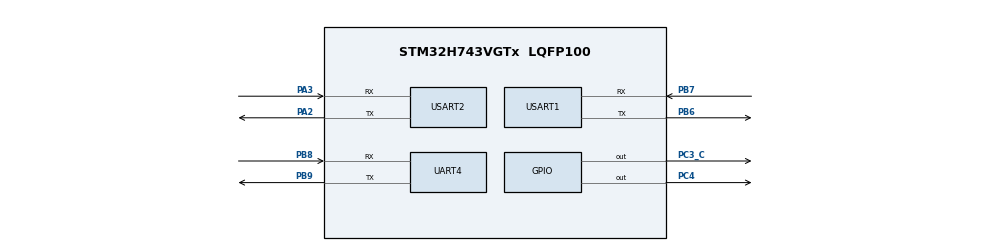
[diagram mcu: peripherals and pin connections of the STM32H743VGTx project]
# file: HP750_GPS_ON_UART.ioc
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Dma.Request0=USART2_RX
Dma.Request1=USART1_TX
Dma.Request2=USART1_RX
Dma.Request3=USART2_TX
Dma.USART1_RX.2.Direction=DMA_PERIPH_TO_MEMORY
Dma.USART1_RX.2.EventEnable=DISABLE
Dma.USART1_RX.2.FIFOMode=DMA_FIFOMODE_DISABLE
Dma.USART1_RX.2.Instance=DMA1_Stream2
Dma.USART1_RX.2.MemDataAlignment=DMA_MDATAALIGN_BYTE
Dma.USART1_RX.2.MemInc=DMA_MINC_ENABLE
Dma.USART1_RX.2.Mode=DMA_NORMAL
Dma.USART1_RX.2.PeriphDataAlignment=DMA_PDATAALIGN_BYTE
Dma.USART1_RX.2.PeriphInc=DMA_PINC_DISABLE
Dma.USART1_RX.2.Polarity=HAL_DMAMUX_REQ_GEN_RISING
Dma.USART1_RX.2.Priority=DMA_PRIORITY_LOW
Dma.USART1_RX.2.RequestNumber=1
Dma.USART1_RX.2.SignalID=NONE
Dma.USART1_RX.2.SyncEnable=DISABLE
Dma.USART1_RX.2.SyncPolarity=HAL_DMAMUX_SYNC_NO_EVENT
Dma.USART1_RX.2.SyncRequestNumber=1
Dma.USART1_RX.2.SyncSignalID=NONE
Dma.USART1_TX.1.Direction=DMA_MEMORY_TO_PERIPH
Dma.USART1_TX.1.EventEnable=DISABLE
Dma.USART1_TX.1.FIFOMode=DMA_FIFOMODE_DISABLE
Dma.USART1_TX.1.Instance=DMA1_Stream0
Dma.USART1_TX.1.MemDataAlignment=DMA_MDATAALIGN_BYTE
Dma.USART1_TX.1.MemInc=DMA_MINC_ENABLE
Dma.USART1_TX.1.Mode=DMA_NORMAL
Dma.USART1_TX.1.PeriphDataAlignment=DMA_PDATAALIGN_BYTE
Dma.USART1_TX.1.PeriphInc=DMA_PINC_DISABLE
Dma.USART1_TX.1.Polarity=HAL_DMAMUX_REQ_GEN_RISING
Dma.USART1_TX.1.Priority=DMA_PRIORITY_LOW
Dma.USART1_TX.1.RequestNumber=1
Dma.USART1_TX.1.SignalID=NONE
Dma.USART1_TX.1.SyncEnable=DISABLE
Dma.USART1_TX.1.SyncPolarity=HAL_DMAMUX_SYNC_NO_EVENT
Dma.USART1_TX.1.SyncRequestNumber=1
Dma.USART1_TX.1.SyncSignalID=NONE
Dma.USART2_RX.0.Direction=DMA_PERIPH_TO_MEMORY
Dma.USART2_RX.0.EventEnable=DISABLE
Dma.USART2_RX.0.FIFOMode=DMA_FIFOMODE_DISABLE
Dma.USART2_RX.0.Instance=DMA1_Stream1
Dma.USART2_RX.0.MemDataAlignment=DMA_MDATAALIGN_BYTE
Dma.USART2_RX.0.MemInc=DMA_MINC_ENABLE
Dma.USART2_RX.0.Mode=DMA_NORMAL
Dma.USART2_RX.0.PeriphDataAlignment=DMA_PDATAALIGN_BYTE
Dma.USART2_RX.0.PeriphInc=DMA_PINC_DISABLE
Dma.USART2_RX.0.Polarity=HAL_DMAMUX_REQ_GEN_RISING
Dma.USART2_RX.0.Priority=DMA_PRIORITY_LOW
Dma.USART2_RX.0.RequestNumber=1
Dma.USART2_RX.0.SignalID=NONE
Dma.USART2_RX.0.SyncEnable=DISABLE
Dma.USART2_RX.0.SyncPolarity=HAL_DMAMUX_SYNC_NO_EVENT
Dma.USART2_RX.0.SyncRequestNumber=1
Dma.USART2_RX.0.SyncSignalID=NONE
Dma.USART2_TX.3.Direction=DMA_MEMORY_TO_PERIPH
Dma.USART2_TX.3.EventEnable=DISABLE
Dma.USART2_TX.3.FIFOMode=DMA_FIFOMODE_DISABLE
Dma.USART2_TX.3.Instance=DMA1_Stream3
Dma.USART2_TX.3.MemDataAlignment=DMA_MDATAALIGN_BYTE
Dma.USART2_TX.3.MemInc=DMA_MINC_ENABLE
Dma.USART2_TX.3.Mode=DMA_NORMAL
Dma.USART2_TX.3.PeriphDataAlignment=DMA_PDATAALIGN_BYTE
Dma.USART2_TX.3.PeriphInc=DMA_PINC_DISABLE
Dma.USART2_TX.3.Polarity=HAL_DMAMUX_REQ_GEN_RISING
Dma.USART2_TX.3.Priority=DMA_PRIORITY_LOW
Dma.USART2_TX.3.RequestNumber=1
Dma.USART2_TX.3.SignalID=NONE
Dma.USART2_TX.3.SyncEnable=DISABLE
Dma.USART2_TX.3.SyncPolarity=HAL_DMAMUX_SYNC_NO_EVENT
Dma.USART2_TX.3.SyncRequestNumber=1
Dma.USART2_TX.3.SyncSignalID=NONE
Mcu.Family=STM32H7
Mcu.Name=STM32H743VGTx
Mcu.Package=LQFP100
NVIC.DMA1_Stream0_IRQn=true\:0\:0\:false\:false\:true\:false\:true\:true
NVIC.DMA1_Stream1_IRQn=true\:0\:0\:false\:false\:true\:false\:true\:true
NVIC.DMA1_Stream2_IRQn=true\:0\:0\:false\:false\:true\:false\:true\:true
NVIC.DMA1_Stream3_IRQn=true\:0\:0\:false\:false\:true\:false\:true\:true
NVIC.PriorityGroup=NVIC_PRIORITYGROUP_4
NVIC.UART4_IRQn=true\:0\:0\:false\:false\:true\:true\:true\:true
NVIC.USART1_IRQn=true\:0\:0\:false\:false\:true\:true\:true\:true
NVIC.USART2_IRQn=true\:0\:0\:false\:false\:true\:true\:true\:true
PA13\ (JTMS/SWDIO).Mode=Serial_Wire
PA13\ (JTMS/SWDIO).Signal=DEBUG_JTMS-SWDIO
PA14\ (JTCK/SWCLK).Mode=Serial_Wire
PA14\ (JTCK/SWCLK).Signal=DEBUG_JTCK-SWCLK
PA2.Mode=Asynchronous
PA2.Signal=USART2_TX
PA3.Mode=Asynchronous
PA3.Signal=USART2_RX
PB6.Mode=Asynchronous
PB6.Signal=USART1_TX
PB7.Mode=Asynchronous
PB7.Signal=USART1_RX
PB8.Mode=Asynchronous
PB8.Signal=UART4_RX
PB9.Mode=Asynchronous
PB9.Signal=UART4_TX
PC14-OSC32_IN\ (OSC32_IN).Mode=LSE-External-Oscillator
PC14-OSC32_IN\ (OSC32_IN).Signal=RCC_OSC32_IN
PC15-OSC32_OUT\ (OSC32_OUT).Mode=LSE-External-Oscillator
PC15-OSC32_OUT\ (OSC32_OUT).Signal=RCC_OSC32_OUT
PC3_C.Signal=GPIO_Output
PC4.Signal=GPIO_Output
PH0-OSC_IN\ (PH0).Mode=HSE-External-Oscillator
PH0-OSC_IN\ (PH0).Signal=RCC_OSC_IN
PH1-OSC_OUT\ (PH1).Mode=HSE-External-Oscillator
PH1-OSC_OUT\ (PH1).Signal=RCC_OSC_OUT
ProjectManager.HeapSize=0x200
ProjectManager.StackSize=0x400
ProjectManager.TargetToolchain=STM32CubeIDE
RCC.ADCFreq_Value=129000000
RCC.APB1Freq_Value=32000000
RCC.APB2Freq_Value=32000000
RCC.APB3Freq_Value=64000000
RCC.APB4Freq_Value=64000000
RCC.CortexFreq_Value=64000000
RCC.D2PPRE1=RCC_APB1_DIV2
RCC.D2PPRE2=RCC_APB2_DIV2
RCC.HCLKFreq_Value=64000000
RCC.HSE_VALUE=16000000
RCC.SYSCLKFreq_VALUE=64000000
RCC.USBFreq_Value=129000000
USART1.VirtualMode-Asynchronous=VM_ASYNC
USART2.VirtualMode-Asynchronous=VM_ASYNC
board=custom

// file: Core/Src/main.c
/* USER CODE BEGIN Header */
/**
  ******************************************************************************
  * @file           : main.c
  * @brief          : Main program body
  ******************************************************************************
  * @attention
  *
  * Copyright (c) 2023 STMicroelectronics.
  * All rights reserved.
  *
  * This software is licensed under terms that can be found in the LICENSE file
  * in the root directory of this software component.
  * If no LICENSE file comes with this software, it is provided AS-IS.
  *
  ******************************************************************************
  */
/* USER CODE END Header */
#include "main.h"

UART_HandleTypeDef huart4;
UART_HandleTypeDef huart1;
UART_HandleTypeDef huart2;
DMA_HandleTypeDef hdma_usart1_tx;
DMA_HandleTypeDef hdma_usart1_rx;
DMA_HandleTypeDef hdma_usart2_rx;
DMA_HandleTypeDef hdma_usart2_tx;

void SystemClock_Config(void);
static void MX_GPIO_Init(void);
static void MX_DMA_Init(void);
static void MX_USART1_UART_Init(void);
static void MX_UART4_Init(void);
static void MX_USART2_UART_Init(void);

/* USER CODE BEGIN 0 */
// Global variables
uint8_t uart2_rx_buffer[300];
uint8_t uart1_tx_buffer[300];

// UART1 receive complete callback
void HAL_UART_RxCpltCallback(UART_HandleTypeDef *huart) {
    if (huart == &huart2) {
        // UART4 data received, copy to UART1 TX buffer
        HAL_UART_Transmit_DMA(&huart1, uart2_rx_buffer, 200);
    }
}

// UART1 transmit complete callback
void HAL_UART_TxCpltCallback(UART_HandleTypeDef *huart) {
    if (huart == &huart1) {
        // UART1 data transmitted, can add additional processing here
    }
}
/* USER CODE END 0 */

int main(void)
{

  /* MCU Configuration--------------------------------------------------------*/

  /* Reset of all peripherals, Initializes the Flash interface and the Systick. */
  HAL_Init();

  /* Configure the system clock */
  SystemClock_Config();

  /* Initialize all configured peripherals */
  MX_GPIO_Init();
  MX_DMA_Init();
  MX_USART1_UART_Init();
  MX_UART4_Init();
  MX_USART2_UART_Init();
  /* USER CODE BEGIN 2 */
  HAL_GPIO_WritePin(GPIOC, GPIO_PIN_4, GPIO_PIN_SET);
  HAL_Delay(500);
  HAL_GPIO_WritePin(GPIOC, GPIO_PIN_3, GPIO_PIN_RESET);
  HAL_Delay(100);
  HAL_GPIO_WritePin(GPIOC, GPIO_PIN_3, GPIO_PIN_SET);

  /* USER CODE END 2 */

  /* Infinite loop */
  /* USER CODE BEGIN WHILE */

  while (1)
  {
	  // Start UART1 DMA receive
	     HAL_UART_Receive_DMA(&huart2, uart2_rx_buffer, 200);

    /* USER CODE END WHILE */

  }
}

void SystemClock_Config(void)
{
  RCC_OscInitTypeDef RCC_OscInitStruct = {0};
  RCC_ClkInitTypeDef RCC_ClkInitStruct = {0};

  /** Supply configuration update enable
  */
  HAL_PWREx_ConfigSupply(PWR_LDO_SUPPLY);

  /** Configure the main internal regulator output voltage
  */
  __HAL_PWR_VOLTAGESCALING_CONFIG(PWR_REGULATOR_VOLTAGE_SCALE3);

  while(!__HAL_PWR_GET_FLAG(PWR_FLAG_VOSRDY)) {}

  /** Initializes the RCC Oscillators according to the specified parameters
  * in the RCC_OscInitTypeDef structure.
  */
  RCC_OscInitStruct.OscillatorType = RCC_OSCILLATORTYPE_HSI;
  RCC_OscInitStruct.HSIState = RCC_HSI_DIV1;
  RCC_OscInitStruct.HSICalibrationValue = RCC_HSICALIBRATION_DEFAULT;
  RCC_OscInitStruct.PLL.PLLState = RCC_PLL_NONE;
  if (HAL_RCC_OscConfig(&RCC_OscInitStruct) != HAL_OK)
  {
    Error_Handler();
  }

  /** Initializes the CPU, AHB and APB buses clocks
  */
  RCC_ClkInitStruct.ClockType = RCC_CLOCKTYPE_HCLK|RCC_CLOCKTYPE_SYSCLK
                              |RCC_CLOCKTYPE_PCLK1|RCC_CLOCKTYPE_PCLK2
                              |RCC_CLOCKTYPE_D3PCLK1|RCC_CLOCKTYPE_D1PCLK1;
  RCC_ClkInitStruct.SYSCLKSource = RCC_SYSCLKSOURCE_HSI;
  RCC_ClkInitStruct.SYSCLKDivider = RCC_SYSCLK_DIV1;
  RCC_ClkInitStruct.AHBCLKDivider = RCC_HCLK_DIV1;
  RCC_ClkInitStruct.APB3CLKDivider = RCC_APB3_DIV1;
  RCC_ClkInitStruct.APB1CLKDivider = RCC_APB1_DIV2;
  RCC_ClkInitStruct.APB2CLKDivider = RCC_APB2_DIV2;
  RCC_ClkInitStruct.APB4CLKDivider = RCC_APB4_DIV1;

  if (HAL_RCC_ClockConfig(&RCC_ClkInitStruct, FLASH_LATENCY_1) != HAL_OK)
  {
    Error_Handler();
  }
}

static void MX_UART4_Init(void)
{

  huart4.Instance = UART4;
  huart4.Init.BaudRate = 115200;
  huart4.Init.WordLength = UART_WORDLENGTH_8B;
  huart4.Init.StopBits = UART_STOPBITS_1;
  huart4.Init.Parity = UART_PARITY_NONE;
  huart4.Init.Mode = UART_MODE_TX_RX;
  huart4.Init.HwFlowCtl = UART_HWCONTROL_NONE;
  huart4.Init.OverSampling = UART_OVERSAMPLING_16;
  huart4.Init.OneBitSampling = UART_ONE_BIT_SAMPLE_DISABLE;
  huart4.Init.ClockPrescaler = UART_PRESCALER_DIV1;
  huart4.AdvancedInit.AdvFeatureInit = UART_ADVFEATURE_NO_INIT;
  if (HAL_UART_Init(&huart4) != HAL_OK)
  {
    Error_Handler();
  }
  if (HAL_UARTEx_SetTxFifoThreshold(&huart4, UART_TXFIFO_THRESHOLD_1_8) != HAL_OK)
  {
    Error_Handler();
  }
  if (HAL_UARTEx_SetRxFifoThreshold(&huart4, UART_RXFIFO_THRESHOLD_1_8) != HAL_OK)
  {
    Error_Handler();
  }
  if (HAL_UARTEx_DisableFifoMode(&huart4) != HAL_OK)
  {
    Error_Handler();
  }

}

static void MX_USART1_UART_Init(void)
{

  huart1.Instance = USART1;
  huart1.Init.BaudRate = 115200;
  huart1.Init.WordLength = UART_WORDLENGTH_8B;
  huart1.Init.StopBits = UART_STOPBITS_1;
  huart1.Init.Parity = UART_PARITY_NONE;
  huart1.Init.Mode = UART_MODE_TX_RX;
  huart1.Init.HwFlowCtl = UART_HWCONTROL_NONE;
  huart1.Init.OverSampling = UART_OVERSAMPLING_16;
  huart1.Init.OneBitSampling = UART_ONE_BIT_SAMPLE_DISABLE;
  huart1.Init.ClockPrescaler = UART_PRESCALER_DIV1;
  huart1.AdvancedInit.AdvFeatureInit = UART_ADVFEATURE_NO_INIT;
  if (HAL_UART_Init(&huart1) != HAL_OK)
  {
    Error_Handler();
  }
  if (HAL_UARTEx_SetTxFifoThreshold(&huart1, UART_TXFIFO_THRESHOLD_1_8) != HAL_OK)
  {
    Error_Handler();
  }
  if (HAL_UARTEx_SetRxFifoThreshold(&huart1, UART_RXFIFO_THRESHOLD_1_8) != HAL_OK)
  {
    Error_Handler();
  }
  if (HAL_UARTEx_DisableFifoMode(&huart1) != HAL_OK)
  {
    Error_Handler();
  }

}

static void MX_USART2_UART_Init(void)
{

  huart2.Instance = USART2;
  huart2.Init.BaudRate = 115200;
  huart2.Init.WordLength = UART_WORDLENGTH_8B;
  huart2.Init.StopBits = UART_STOPBITS_1;
  huart2.Init.Parity = UART_PARITY_NONE;
  huart2.Init.Mode = UART_MODE_TX_RX;
  huart2.Init.HwFlowCtl = UART_HWCONTROL_NONE;
  huart2.Init.OverSampling = UART_OVERSAMPLING_16;
  huart2.Init.OneBitSampling = UART_ONE_BIT_SAMPLE_DISABLE;
  huart2.Init.ClockPrescaler = UART_PRESCALER_DIV1;
  huart2.AdvancedInit.AdvFeatureInit = UART_ADVFEATURE_NO_INIT;
  if (HAL_UART_Init(&huart2) != HAL_OK)
  {
    Error_Handler();
  }
  if (HAL_UARTEx_SetTxFifoThreshold(&huart2, UART_TXFIFO_THRESHOLD_1_8) != HAL_OK)
  {
    Error_Handler();
  }
  if (HAL_UARTEx_SetRxFifoThreshold(&huart2, UART_RXFIFO_THRESHOLD_1_8) != HAL_OK)
  {
    Error_Handler();
  }
  if (HAL_UARTEx_DisableFifoMode(&huart2) != HAL_OK)
  {
    Error_Handler();
  }

}

static void MX_DMA_Init(void)
{

  /* DMA controller clock enable */
  __HAL_RCC_DMA1_CLK_ENABLE();

  /* DMA interrupt init */
  /* DMA1_Stream0_IRQn interrupt configuration */
  HAL_NVIC_SetPriority(DMA1_Stream0_IRQn, 0, 0);
  HAL_NVIC_EnableIRQ(DMA1_Stream0_IRQn);
  /* DMA1_Stream1_IRQn interrupt configuration */
  HAL_NVIC_SetPriority(DMA1_Stream1_IRQn, 0, 0);
  HAL_NVIC_EnableIRQ(DMA1_Stream1_IRQn);
  /* DMA1_Stream2_IRQn interrupt configuration */
  HAL_NVIC_SetPriority(DMA1_Stream2_IRQn, 0, 0);
  HAL_NVIC_EnableIRQ(DMA1_Stream2_IRQn);
  /* DMA1_Stream3_IRQn interrupt configuration */
  HAL_NVIC_SetPriority(DMA1_Stream3_IRQn, 0, 0);
  HAL_NVIC_EnableIRQ(DMA1_Stream3_IRQn);

}

static void MX_GPIO_Init(void)
{
  GPIO_InitTypeDef GPIO_InitStruct = {0};

  /* GPIO Ports Clock Enable */
  __HAL_RCC_GPIOC_CLK_ENABLE();
  __HAL_RCC_GPIOH_CLK_ENABLE();
  __HAL_RCC_GPIOA_CLK_ENABLE();
  __HAL_RCC_GPIOB_CLK_ENABLE();

  /*Configure GPIO pin Output Level */
  HAL_GPIO_WritePin(GPIOC, GPIO_PIN_3|GPIO_PIN_4, GPIO_PIN_RESET);

  /*Configure GPIO pins : PC3 PC4 */
  GPIO_InitStruct.Pin = GPIO_PIN_3|GPIO_PIN_4;
  GPIO_InitStruct.Mode = GPIO_MODE_OUTPUT_PP;
  GPIO_InitStruct.Pull = GPIO_NOPULL;
  GPIO_InitStruct.Speed = GPIO_SPEED_FREQ_LOW;
  HAL_GPIO_Init(GPIOC, &GPIO_InitStruct);

}

void Error_Handler(void)
{
  __disable_irq();
  while (1)
  {
  }
}
